# VPAC0_DRU_UTC_VPAC0_DRU_MMR_CFG_DRU_DRU_CHNRT register map
Vendor: Texas Instruments
Peripheral module from a debugger description file (folder J7ES).
Registers are 64-bit, access per field, reset 0x0 unless marked. A register's access mark holds for its fields unless they carry their own. Offsets are as the file gives them; lines under a group give offsets from that group; [hi:lo] are bit positions; {n}, {i} and the like mark numbered series; 'fields as' and 'values as' point back to an identical list; <NAME> marks a mode.

## VPAC0_DRU_UTC_VPAC0_DRU_MMR_CFG_DRU_DRU_CHNRT
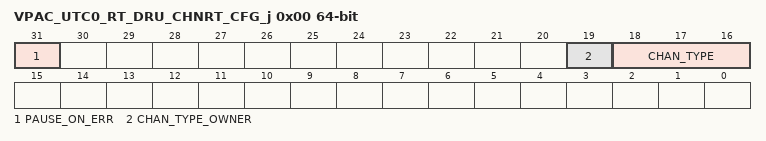
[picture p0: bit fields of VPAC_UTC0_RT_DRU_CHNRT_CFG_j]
0x00 VPAC_UTC0_RT_DRU_CHNRT_CFG_j — Channel Configuration Register. The Channel Configuration Register is used to initialize static mode settings for the DMA Channel. The register may only be written when the chanel is disable in the ch_enable field in the REALTIME CONTROL register is 0. Offset = 00240000h + (j * 100h); where j = 0h to 1Fh
  [31] PAUSE_ON_ERR rw — Pause on Error.
  [19] CHAN_TYPE_OWNER rw — This field controls how the TR is received by the UTC.
  [18:16] CHAN_TYPE ro — This field states the TR type that is being used it along with CHAN_TYPE_OWNER field make up the 4 bit CHAN_TYPE for a KS3 DMA UTC.
0x20 VPAC_UTC0_RT_DRU_CHNRT_CHOES0_j — The Output Event Steering Registers are used to specify a global event number to generate anytime the required event generation criteria specified in a TR are met. A single event with the event number set equal to the value in the corresponding register will be generated. This register is provided in order to allow security SW to lock down which events in the global space any given channel/ thread is allowed to generate Offset = 00240020h + (j * 100h); where j = 0h to 1Fh
  [15:0] EVT_NUM rw — This is the global event number to be generated.
0x60 VPAC_UTC0_RT_DRU_CHNRT_CHST_SCHED_j rw — Channel Static Scheduler Config Register Offset = 00240060h + (j * 100h); where j = 0h to 1Fh
  [2:0] QUEUE — This is the queue number that is written
